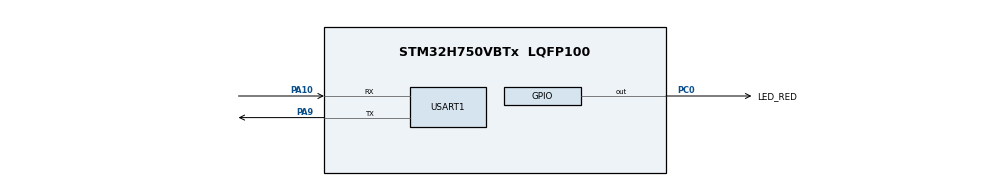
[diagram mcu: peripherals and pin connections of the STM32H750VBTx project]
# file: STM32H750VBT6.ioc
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Mcu.Family=STM32H7
Mcu.Name=STM32H750VBTx
Mcu.Package=LQFP100
NVIC.PriorityGroup=NVIC_PRIORITYGROUP_4
PA10.Mode=Asynchronous
PA10.Signal=USART1_RX
PA13\ (JTMS/SWDIO).Mode=Serial_Wire
PA13\ (JTMS/SWDIO).Signal=SYS_JTMS-SWDIO
PA14\ (JTCK/SWCLK).Mode=Serial_Wire
PA14\ (JTCK/SWCLK).Signal=SYS_JTCK-SWCLK
PA9.Mode=Asynchronous
PA9.Signal=USART1_TX
PC0.GPIO_Label=LED_RED
PC0.Signal=GPIO_Output
PH0-OSC_IN\ (PH0).Mode=HSE-External-Oscillator
PH0-OSC_IN\ (PH0).Signal=RCC_OSC_IN
PH1-OSC_OUT\ (PH1).Mode=HSE-External-Oscillator
PH1-OSC_OUT\ (PH1).Signal=RCC_OSC_OUT
ProjectManager.HeapSize=0x200
ProjectManager.StackSize=0x400
ProjectManager.TargetToolchain=MDK-ARM V5
RCC.ADCFreq_Value=16125000
RCC.APB1Freq_Value=100000000
RCC.APB2Freq_Value=100000000
RCC.APB3Freq_Value=100000000
RCC.APB4Freq_Value=100000000
RCC.CortexFreq_Value=400000000
RCC.D1PPRE=RCC_APB3_DIV2
RCC.D2PPRE1=RCC_APB1_DIV2
RCC.D2PPRE2=RCC_APB2_DIV2
RCC.D3PPRE=RCC_APB4_DIV2
RCC.DIVM1=1
RCC.DIVN1=100
RCC.EnbaleCSS=true
RCC.HCLKFreq_Value=200000000
RCC.HPRE=RCC_HCLK_DIV2
RCC.HSE_VALUE=8000000
RCC.PLLSourceVirtual=RCC_PLLSOURCE_HSE
RCC.SYSCLKFreq_VALUE=400000000
RCC.SYSCLKSource=RCC_SYSCLKSOURCE_PLLCLK
RCC.USBFreq_Value=400000000
USART1.VirtualMode-Asynchronous=VM_ASYNC
board=custom

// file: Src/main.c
/* USER CODE BEGIN Header */
/**
  ******************************************************************************
  * @file           : main.c
  * @brief          : Main program body
  ******************************************************************************
  ** This notice applies to any and all portions of this file
  * that are not between comment pairs USER CODE BEGIN and
  * USER CODE END. Other portions of this file, whether
  * inserted by the user or by software development tools
  * are owned by their respective copyright owners.
  *
  * COPYRIGHT(c) 2020 STMicroelectronics
  *
  * Redistribution and use in source and binary forms, with or without modification,
  * are permitted provided that the following conditions are met:
  *   1. Redistributions of source code must retain the above copyright notice,
  *      this list of conditions and the following disclaimer.
  *   2. Redistributions in binary form must reproduce the above copyright notice,
  *      this list of conditions and the following disclaimer in the documentation
  *      and/or other materials provided with the distribution.
  *   3. Neither the name of STMicroelectronics nor the names of its contributors
  *      may be used to endorse or promote products derived from this software
  *      without specific prior written permission.
  *
  * THIS SOFTWARE IS PROVIDED BY THE COPYRIGHT HOLDERS AND CONTRIBUTORS "AS IS"
  * AND ANY EXPRESS OR IMPLIED WARRANTIES, INCLUDING, BUT NOT LIMITED TO, THE
  * IMPLIED WARRANTIES OF MERCHANTABILITY AND FITNESS FOR A PARTICULAR PURPOSE ARE
  * DISCLAIMED. IN NO EVENT SHALL THE COPYRIGHT HOLDER OR CONTRIBUTORS BE LIABLE
  * FOR ANY DIRECT, INDIRECT, INCIDENTAL, SPECIAL, EXEMPLARY, OR CONSEQUENTIAL
  * DAMAGES (INCLUDING, BUT NOT LIMITED TO, PROCUREMENT OF SUBSTITUTE GOODS OR
  * SERVICES; LOSS OF USE, DATA, OR PROFITS; OR BUSINESS INTERRUPTION) HOWEVER
  * CAUSED AND ON ANY THEORY OF LIABILITY, WHETHER IN CONTRACT, STRICT LIABILITY,
  * OR TORT (INCLUDING NEGLIGENCE OR OTHERWISE) ARISING IN ANY WAY OUT OF THE USE
  * OF THIS SOFTWARE, EVEN IF ADVISED OF THE POSSIBILITY OF SUCH DAMAGE.
  *
  ******************************************************************************
  */
/* USER CODE END Header */

#include "main.h"
#include "usart.h"
#include "gpio.h"

void SystemClock_Config(void);

int main(void)
{

  /* MCU Configuration--------------------------------------------------------*/

  /* Reset of all peripherals, Initializes the Flash interface and the Systick. */
  HAL_Init();

  /* Configure the system clock */
  SystemClock_Config();

  /* Initialize all configured peripherals */
  MX_GPIO_Init();
  MX_USART1_UART_Init();

  /* Infinite loop */
  while (1)
  {

    /* USER CODE BEGIN 3 */

    uint8_t buffer[]={'a','b','c'};

    HAL_GPIO_WritePin(LED_RED_GPIO_Port,LED_RED_Pin,GPIO_PIN_SET);
    HAL_UART_Transmit(&huart1,&buffer[0],1,100);
    HAL_Delay(1000);

    HAL_GPIO_WritePin(LED_RED_GPIO_Port,LED_RED_Pin,GPIO_PIN_RESET);
    HAL_UART_Transmit(&huart1,&buffer[1],1,100);
    HAL_Delay(1000);

  }
  /* USER CODE END 3 */
}

void SystemClock_Config(void)
{
  RCC_OscInitTypeDef RCC_OscInitStruct = {0};
  RCC_ClkInitTypeDef RCC_ClkInitStruct = {0};
  RCC_PeriphCLKInitTypeDef PeriphClkInitStruct = {0};

  /**Configure the main internal regulator output voltage
  */
  __HAL_PWR_VOLTAGESCALING_CONFIG(PWR_REGULATOR_VOLTAGE_SCALE1);

  while ((PWR->D3CR & (PWR_D3CR_VOSRDY)) != PWR_D3CR_VOSRDY)
  {

  }
  /**Initializes the CPU, AHB and APB busses clocks
  */
  RCC_OscInitStruct.OscillatorType = RCC_OSCILLATORTYPE_HSE;
  RCC_OscInitStruct.HSEState = RCC_HSE_ON;
  RCC_OscInitStruct.PLL.PLLState = RCC_PLL_ON;
  RCC_OscInitStruct.PLL.PLLSource = RCC_PLLSOURCE_HSE;
  RCC_OscInitStruct.PLL.PLLM = 1;
  RCC_OscInitStruct.PLL.PLLN = 100;
  RCC_OscInitStruct.PLL.PLLP = 2;
  RCC_OscInitStruct.PLL.PLLQ = 2;
  RCC_OscInitStruct.PLL.PLLR = 2;
  RCC_OscInitStruct.PLL.PLLRGE = RCC_PLL1VCIRANGE_3;
  RCC_OscInitStruct.PLL.PLLVCOSEL = RCC_PLL1VCOWIDE;
  RCC_OscInitStruct.PLL.PLLFRACN = 0;
  if (HAL_RCC_OscConfig(&RCC_OscInitStruct) != HAL_OK)
  {
    Error_Handler();
  }
  /**Initializes the CPU, AHB and APB busses clocks
  */
  RCC_ClkInitStruct.ClockType = RCC_CLOCKTYPE_HCLK|RCC_CLOCKTYPE_SYSCLK
                              |RCC_CLOCKTYPE_PCLK1|RCC_CLOCKTYPE_PCLK2
                              |RCC_CLOCKTYPE_D3PCLK1|RCC_CLOCKTYPE_D1PCLK1;
  RCC_ClkInitStruct.SYSCLKSource = RCC_SYSCLKSOURCE_PLLCLK;
  RCC_ClkInitStruct.SYSCLKDivider = RCC_SYSCLK_DIV1;
  RCC_ClkInitStruct.AHBCLKDivider = RCC_HCLK_DIV2;
  RCC_ClkInitStruct.APB3CLKDivider = RCC_APB3_DIV2;
  RCC_ClkInitStruct.APB1CLKDivider = RCC_APB1_DIV2;
  RCC_ClkInitStruct.APB2CLKDivider = RCC_APB2_DIV2;
  RCC_ClkInitStruct.APB4CLKDivider = RCC_APB4_DIV2;

  if (HAL_RCC_ClockConfig(&RCC_ClkInitStruct, FLASH_LATENCY_2) != HAL_OK)
  {
    Error_Handler();
  }
  PeriphClkInitStruct.PeriphClockSelection = RCC_PERIPHCLK_USART1;
  PeriphClkInitStruct.Usart16ClockSelection = RCC_USART16CLKSOURCE_D2PCLK2;
  if (HAL_RCCEx_PeriphCLKConfig(&PeriphClkInitStruct) != HAL_OK)
  {
    Error_Handler();
  }
  /**Enables the Clock Security System
  */
  HAL_RCC_EnableCSS();
}

void Error_Handler(void)
{
}

/************************ (C) COPYRIGHT STMicroelectronics *****END OF FILE****/
